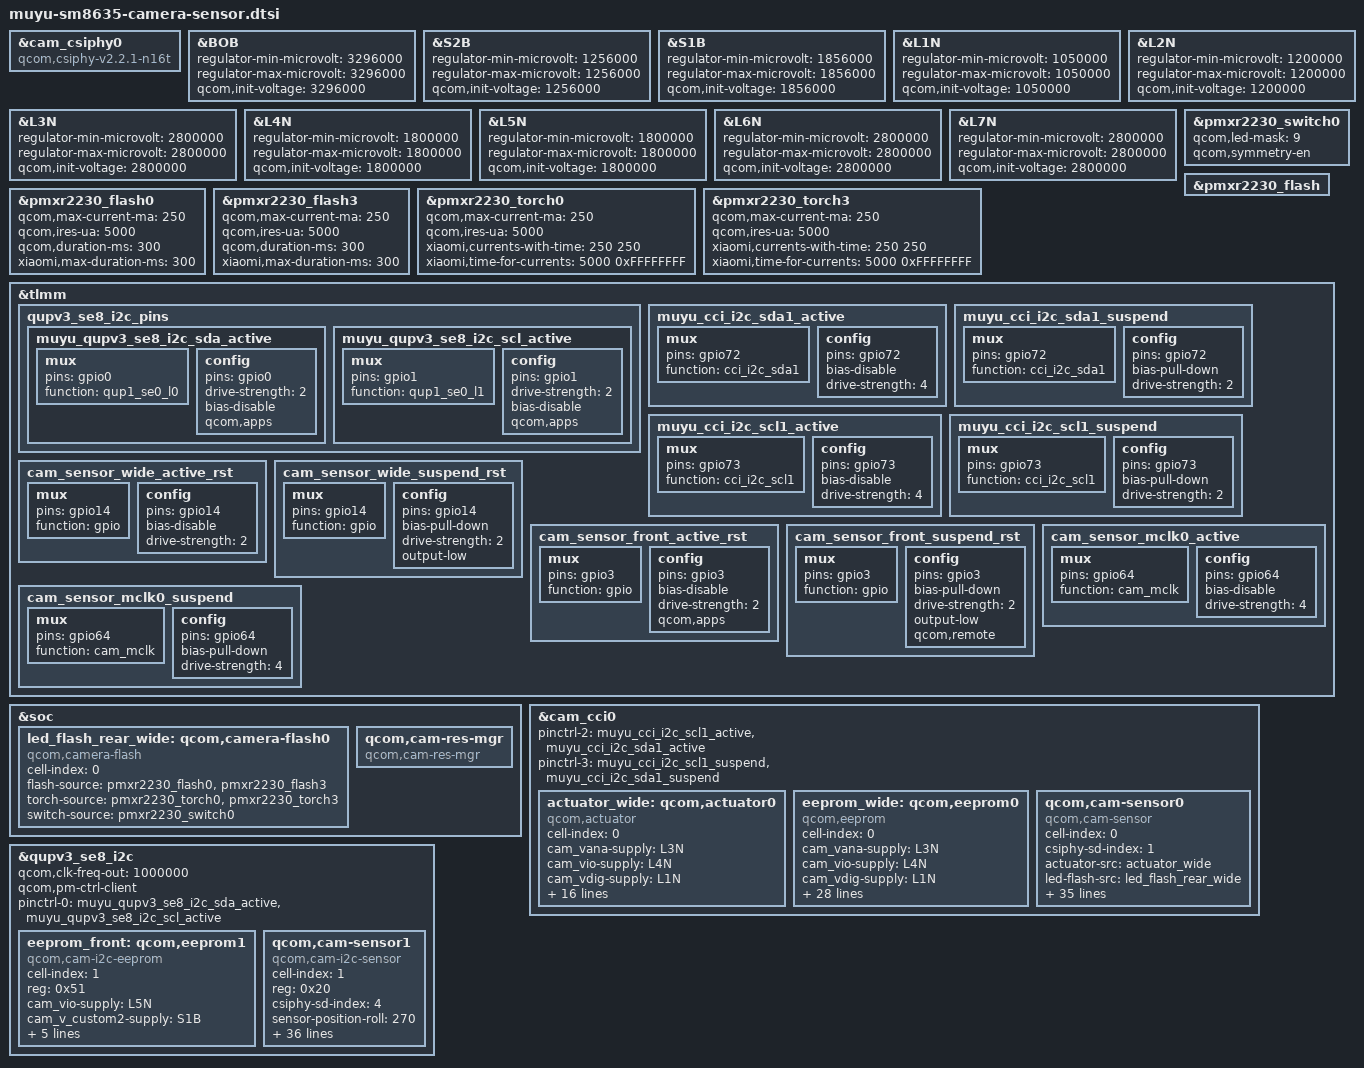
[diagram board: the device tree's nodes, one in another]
#include <dt-bindings/msm-camera.h>

//wide
&cam_csiphy0 {
	compatible = "qcom,csiphy-v2.2.1-n16t", "qcom,csiphy";
};
&BOB {
	regulator-min-microvolt = <3296000>;
	regulator-max-microvolt = <3296000>;
	qcom,init-voltage = <3296000>;
};
&S2B {
	regulator-min-microvolt = <1256000>;
	regulator-max-microvolt = <1256000>;
	qcom,init-voltage = <1256000>;
};

&S1B {
	regulator-min-microvolt = <1856000>;
	regulator-max-microvolt = <1856000>;
	qcom,init-voltage = <1856000>;
};

&L1N {
	regulator-min-microvolt = <1050000>;
	regulator-max-microvolt = <1050000>;
	qcom,init-voltage = <1050000>;
};

&L2N {
	regulator-min-microvolt = <1200000>;
	regulator-max-microvolt = <1200000>;
	qcom,init-voltage = <1200000>;
};
&L3N {
	regulator-min-microvolt = <2800000>;
	regulator-max-microvolt = <2800000>;
	qcom,init-voltage = <2800000>;
};

&L4N {
	regulator-min-microvolt = <1800000>;
	regulator-max-microvolt = <1800000>;
	qcom,init-voltage = <1800000>;
};
&L5N {
	regulator-min-microvolt = <1800000>;
	regulator-max-microvolt = <1800000>;
	qcom,init-voltage = <1800000>;
};

&L6N {
	regulator-min-microvolt = <2800000>;
	regulator-max-microvolt = <2800000>;
	qcom,init-voltage = <2800000>;
};
&L7N {
	regulator-min-microvolt = <2800000>;
	regulator-max-microvolt = <2800000>;
	qcom,init-voltage = <2800000>;
};

&pmxr2230_switch0 {
    qcom,led-mask = <9>; /* Channels 1 & 4 */
    qcom,symmetry-en;
};

&pmxr2230_flash {
	status = "ok";
};

&pmxr2230_flash0 {
	qcom,max-current-ma = <250>;
        qcom,ires-ua = <5000>;
	qcom,duration-ms = <300>;
	xiaomi,max-duration-ms = <300>;
};

&pmxr2230_flash3 {
	qcom,max-current-ma = <250>;
        qcom,ires-ua = <5000>;
	qcom,duration-ms = <300>;
	xiaomi,max-duration-ms = <300>;
};

&pmxr2230_torch0 {
	qcom,max-current-ma = <250>;
        qcom,ires-ua = <5000>;
	xiaomi,currents-with-time = <250 250>;
	xiaomi,time-for-currents = <5000 0xFFFFFFFF>;  /* 0xFFFFFFFF means flash always on*/
};

&pmxr2230_torch3 {
	qcom,max-current-ma = <250>;
        qcom,ires-ua = <5000>;
	xiaomi,currents-with-time = <250 250>;
	xiaomi,time-for-currents = <5000 0xFFFFFFFF>;  /* 0xFFFFFFFF means flash always on*/
};

&tlmm {
	qupv3_se8_i2c_pins: qupv3_se8_i2c_pins {
		muyu_qupv3_se8_i2c_sda_active: muyu_qupv3_se8_i2c_sda_active {
			mux {
				pins = "gpio0";
				function = "qup1_se0_l0";
			};

			config {
				pins = "gpio0";
				drive-strength = <2>;
				bias-disable; /* NO PULL */
				qcom,apps;
			};
		};

		muyu_qupv3_se8_i2c_scl_active: muyu_qupv3_se8_i2c_scl_active {
			mux {
				pins = "gpio1";
				function = "qup1_se0_l1";
			};

			config {
				pins = "gpio1";
				drive-strength = <2>;
				bias-disable; /* NO PULL */
				qcom,apps;
			};
		};
	};

	muyu_cci_i2c_sda1_active: muyu_cci_i2c_sda1_active {
		mux {
			/* CLK, DATA */
			pins = "gpio72";
			function = "cci_i2c_sda1";
		};

		config {
			pins = "gpio72";
			bias-disable; /* NO PULL */
			drive-strength = <4>; /* 4 MA */
		};
	};

	muyu_cci_i2c_sda1_suspend: muyu_cci_i2c_sda1_suspend {
		mux {
			/* CLK, DATA */
			pins = "gpio72";
			function = "cci_i2c_sda1";
		};

		config {
			pins = "gpio72";
			bias-pull-down; /* PULL DOWN */
			drive-strength = <2>; /* 2 MA */
		};
	};
	muyu_cci_i2c_scl1_active: muyu_cci_i2c_scl1_active {
		mux {
			/* CLK, DATA */
			pins = "gpio73";
			function = "cci_i2c_scl1";
		};

		config {
			pins = "gpio73";
			bias-disable; /* NO PULL */
			drive-strength = <4>; /* 4 MA */
		};
	};

	muyu_cci_i2c_scl1_suspend: muyu_cci_i2c_scl1_suspend {
		mux {
			/* CLK, DATA */
			pins = "gpio73";
			function = "cci_i2c_scl1";
		};

		config {
			pins = "gpio73";
			bias-pull-down; /* PULL DOWN */
			drive-strength = <2>; /* 2 MA */
		};
	};

	cam_sensor_wide_active_rst: cam_sensor_wide_active_rst {
		mux {
			pins = "gpio14";
			function = "gpio";
		};

		config {
			pins = "gpio14";
			bias-disable; /* No PULL */
			drive-strength = <2>; /* 2 MA */
		};
	};

	cam_sensor_wide_suspend_rst: cam_sensor_wide_suspend_rst {
		mux {
			pins = "gpio14";
			function = "gpio";
		};

		config {
			pins = "gpio14";
			bias-pull-down; /* PULL DOWN */
			drive-strength = <2>; /* 2 MA */
			output-low;
		};
	};

	cam_sensor_front_active_rst: cam_sensor_front_active_rst {
		mux {
			pins = "gpio3";
			function = "gpio";
		};

		config {
			pins = "gpio3";
			bias-disable;
			drive-strength = <2>;
			qcom,apps;
		};
	};

	cam_sensor_front_suspend_rst: cam_sensor_front_suspend_rst {
		mux {
			pins = "gpio3";
			function = "gpio";
		};

		config {
			pins = "gpio3";
			bias-pull-down;
			drive-strength = <2>;
			output-low;
			qcom,remote;
		};
	};
	cam_sensor_mclk0_active: cam_sensor_mclk0_active {
		mux {
			pins = "gpio64";
			function = "cam_mclk";
		};

		config {
			pins = "gpio64";
			bias-disable; /* No PULL */
			drive-strength = <4>; /* 4 MA */
		};
	};

	cam_sensor_mclk0_suspend: cam_sensor_mclk0_suspend {
		mux {
			pins = "gpio64";
			function = "cam_mclk";
		};

		config {
			pins = "gpio64";
			bias-pull-down; /* PULL DOWN */
			drive-strength = <4>; /* 4 MA */
		};
	};
/*
	cam_sensor_mclk4_active: cam_sensor_mclk4_active {
		mux {
			pins = "gpio68";
			function = "cam_aon_mclk4";
		};
		config {
			pins = "gpio68";
			bias-disable;
			drive-strength = <4>;
		};
	};
	cam_sensor_mclk4_suspend: cam_sensor_mclk4_suspend {
		mux {
			pins = "gpio68";
			function = "cam_aon_mclk4";
		};
		config {
			pins = "gpio68";
			bias-pull-down;
			drive-strength = <4>;
		};
	};
*/
};
&soc {
	led_flash_rear_wide: qcom,camera-flash0 {
		cell-index = <0>;
		compatible = "qcom,camera-flash";
		flash-source = <&pmxr2230_flash0 &pmxr2230_flash3>;
		torch-source = <&pmxr2230_torch0 &pmxr2230_torch3>;
		switch-source = <&pmxr2230_switch0>;
		status = "ok";
	};
	qcom,cam-res-mgr {
		compatible = "qcom,cam-res-mgr";
		status = "ok";
	};
};

&cam_cci0 {
        pinctrl-2 = <&muyu_cci_i2c_scl1_active &muyu_cci_i2c_sda1_active>;
        pinctrl-3 = <&muyu_cci_i2c_scl1_suspend &muyu_cci_i2c_sda1_suspend>;

	actuator_wide: qcom,actuator0 {
		cell-index = <0>;
		compatible = "qcom,actuator";
		cam_vana-supply = <&L3N>;
		cam_vio-supply = <&L4N>;
		cam_vdig-supply = <&L1N>;
		cam_vaf-supply = <&L7N>;
		cam_clk-supply = <&cam_cc_titan_top_gdsc>;
                cam_v_custom1-supply = <&S2B>;
                cam_bob-supply = <&BOB>;
		regulator-names = "cam_vana", "cam_vio", "cam_vdig", "cam_vaf";
		rgltr-cntrl-support;
		rgltr-min-voltage = <2800000 1800000 1050000 2800000>;
		rgltr-max-voltage = <2800000 1800000 1050000 2800000>;
		rgltr-load-current = <90000 3000 290000 120000>;
		cci-master = <CCI_MASTER_1>;
		clocks = <&camcc CAM_CC_MCLK0_CLK>;
		clock-names = "cam_clk";
		clock-cntl-level = "nominal";
		clock-rates = <19200000>;
		status = "ok";
	};

	eeprom_wide: qcom,eeprom0 {
                cell-index = <0>;
                compatible = "qcom,eeprom";
		cam_vana-supply = <&L3N>;
		cam_vio-supply = <&L4N>;
		cam_vdig-supply = <&L1N>;
		cam_vaf-supply = <&L7N>;
		cam_clk-supply = <&cam_cc_titan_top_gdsc>;
                cam_v_custom1-supply = <&S2B>;
                cam_bob-supply = <&BOB>;
		regulator-names = "cam_vana", "cam_vio", "cam_vdig", "cam_vaf",
                                "cam_clk","cam_v_custom1" ,"cam_bob";
		rgltr-cntrl-support;
		rgltr-min-voltage = <2800000 1800000 1050000 2800000 0 1256000 3296000>;
		rgltr-max-voltage = <2800000 1800000 1050000 2800000 0 1256000 3296000>;
		rgltr-load-current = <90000 3000 290000 120000 0 454000 103000>;
		gpio-no-mux = <0>;
		pinctrl-names = "cam_default", "cam_suspend";
		pinctrl-0 = <&cam_sensor_mclk0_active
			&cam_sensor_wide_active_rst>;
		pinctrl-1 = <&cam_sensor_mclk0_suspend
			&cam_sensor_wide_suspend_rst>;
		gpios = <&tlmm 64 0>, <&tlmm 14 0>;
		gpio-reset = <1>;
		gpio-req-tbl-num = <0 1>;
		gpio-req-tbl-flags = <1 0>;
		gpio-req-tbl-label = "CAMIF_MCLK0", "CAM_RESET_WIDE";
		cci-master = <CCI_MASTER_1>;
		clocks = <&camcc CAM_CC_MCLK0_CLK>;
		clock-names = "cam_clk";
		clock-cntl-level = "nominal";
		clock-rates = <19200000>;
		status = "ok";
        };

	//Wide S5KJN1
	qcom,cam-sensor0 {
		cell-index = <0>;
		compatible = "qcom,cam-sensor";
		csiphy-sd-index = <1>;
		actuator-src = <&actuator_wide>;
		led-flash-src = <&led_flash_rear_wide>;
		eeprom-src = <&eeprom_wide>;
		sensor-position-roll = <90>;
		sensor-position-pitch = <0>;
		sensor-position-yaw = <180>;
		cam_vana-supply = <&L3N>;
		cam_vio-supply = <&L4N>;
		cam_vdig-supply = <&L1N>;
		cam_vaf-supply = <&L7N>;
		cam_clk-supply = <&cam_cc_titan_top_gdsc>;
                cam_v_custom1-supply = <&S2B>;
                cam_bob-supply = <&BOB>;
		regulator-names = "cam_vana", "cam_vio", "cam_vdig", "cam_vaf",
                                "cam_clk","cam_v_custom1" ,"cam_bob";
		rgltr-cntrl-support;
		rgltr-min-voltage = <2800000 1800000 1050000 2800000 0 1256000 3296000>;
		rgltr-max-voltage = <2800000 1800000 1050000 2800000 0 1256000 3296000>;
		rgltr-load-current = <90000 3000 290000 120000 0 454000 103000>;
		gpio-no-mux = <0>;
		pinctrl-names = "cam_default", "cam_suspend";
		pinctrl-0 = <&cam_sensor_mclk0_active
			&cam_sensor_wide_active_rst>;
		pinctrl-1 = <&cam_sensor_mclk0_suspend
			&cam_sensor_wide_suspend_rst>;
		gpios = <&tlmm 64 0>, <&tlmm 14 0>;
		gpio-reset = <1>;
		gpio-req-tbl-num = <0 1>;
		gpio-req-tbl-flags = <1 0>;
		gpio-req-tbl-label = "CAMIF_MCLK0", "CAM_RESET_WIDE";
		cci-master = <CCI_MASTER_1>;
		clocks = <&camcc CAM_CC_MCLK0_CLK>;
		clock-names = "cam_clk";
		clock-cntl-level = "nominal";
		clock-rates = <19200000>;
		status = "ok";
	};
};

&qupv3_se8_i2c {
	status = "ok";
	qcom,clk-freq-out = <1000000>;
	qcom,pm-ctrl-client;

	//Remove I2C gpio pull-up setting for resolve voltage step
	pinctrl-0 = <&muyu_qupv3_se8_i2c_sda_active>, <&muyu_qupv3_se8_i2c_scl_active>;

	//front eeprom
	eeprom_front: qcom,eeprom1 {
		cell-index = <1>;
		reg = <0x51>;
		compatible = "qcom,cam-i2c-eeprom";
		cam_vio-supply = <&L5N>;
                cam_v_custom2-supply = <&S1B>;
		regulator-names = "cam_vio", "cam_v_custom2";
		rgltr-cntrl-support;
		rgltr-min-voltage = <1800000 1856000>;
		rgltr-max-voltage = <1800000 1856000>;
		rgltr-load-current = <2000 6340000>;
		status = "ok";
	};

	// Front OV32D40
	qcom,cam-sensor1 {
		cell-index = <1>;
		reg = <0x20>;
		compatible = "qcom,cam-i2c-sensor";
		csiphy-sd-index = <4>;
		sensor-position-roll = <270>;
		sensor-position-pitch = <0>;
		sensor-position-yaw = <0>;
		eeprom-src = <&eeprom_front>;
                aon-camera-id = <AON_CAM1>;
		cam_vana-supply = <&L6N>;
		cam_vio-supply = <&L5N>;
		cam_vdig-supply = <&L2N>;
                cam_v_custom1-supply = <&S2B>;
                cam_v_custom2-supply = <&S1B>;
                cam_bob-supply = <&BOB>;
		cam_clk-supply = <&cam_cc_titan_top_gdsc>;
		regulator-names = "cam_vana", "cam_vio",
			"cam_vdig", "cam_clk" ,"cam_v_custom1" ,"cam_v_custom2", "cam_bob";
		rgltr-cntrl-support;
		rgltr-min-voltage = <2800000 1800000 1200000 0 1256000 1856000 3296000>;
		rgltr-max-voltage = <2800000 1800000 1200000 0 1256000 1856000 3296000>;
		rgltr-load-current =  <42000 2000 67000 0 454000 6340000 103000>;
		gpio-no-mux = <0>;
		use-shared-clk;
		pinctrl-names = "cam_default", "cam_suspend";
		pinctrl-0 = <&cam_sensor_mclk4_active
			&cam_sensor_front_active_rst>;
		pinctrl-1 = <&cam_sensor_mclk4_suspend
			&cam_sensor_front_suspend_rst>;

		gpios = <&tlmm 68 0>, <&tlmm 3 0>;
		gpio-reset = <1>;
		gpio-req-tbl-num = <0 1>;
		gpio-req-tbl-flags = <1 0>;
		gpio-req-tbl-label = "CAMIF_MCLK4", "CAM_RESET_FRONT";
		//cci-master = <CCI_MASTER_1>;
		clocks = <&camcc CAM_CC_MCLK4_CLK>;
		clock-names = "cam_clk";
		clock-cntl-level = "nominal";
		clock-rates = <19200000>;
		status = "ok";
	};
};
